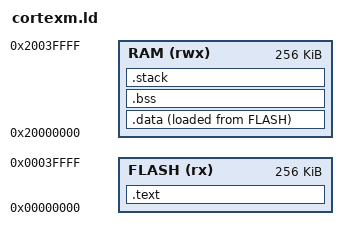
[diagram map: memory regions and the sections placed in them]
ENTRY(Reset_Handler)

MEMORY {
    FLASH (rx)  : ORIGIN = 0x00000000, LENGTH = 256K
    RAM   (rwx) : ORIGIN = 0x20000000, LENGTH = 256K
}

SECTIONS {
    .text : {
        KEEP(*(.vectors))
        *(.text*)
        *(.rodata*)
        . = ALIGN(4);
    } > FLASH

    _sidata = LOADADDR(.data);
    .data : {
        _sdata = .;
        *(.data*)
        . = ALIGN(4);
        _edata = .;
    } > RAM AT > FLASH

    .bss : {
        _sbss = .;
        *(.bss*)
        *(COMMON)
        . = ALIGN(4);
        _ebss = .;
    } > RAM

    .stack (NOLOAD) : {
        . = ALIGN(8);
        . += 0x400;
        __StackTop = .;
    } > RAM
}
